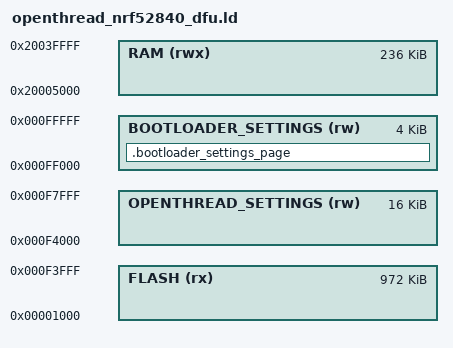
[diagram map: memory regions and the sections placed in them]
/* Linker script to configure memory regions. */

SEARCH_DIR(.)
GROUP(-lgcc -lc -lnosys)

MEMORY
{
  FLASH (rx) : ORIGIN = 0x1000, LENGTH = 0xF3000
  RAM (rwx) :  ORIGIN = 0x20005000, LENGTH = 0x3B000

  /** Location of bootloader setting in flash. */
  BOOTLOADER_SETTINGS (rw) : ORIGIN = 0x000FF000, LENGTH = 0x1000

  /** Location of OpenThread settings in flash. */
  OPENTHREAD_SETTINGS (rw) : ORIGIN = 0x000F4000, LENGTH = 0x4000
}

SECTIONS
{
  /* Place the bootloader settings page in flash. */
  .bootloader_settings_page(NOLOAD) :
  {

  } > BOOTLOADER_SETTINGS
}

SECTIONS
{
  . = ALIGN(4);
  .svc_data :
  {
    PROVIDE(__start_svc_data = .);
    KEEP(*(.svc_data))
    PROVIDE(__stop_svc_data = .);
  } > RAM
  .fs_data :
  {
    PROVIDE(__start_fs_data = .);
    KEEP(*(.fs_data))
    PROVIDE(__stop_fs_data = .);
  } > RAM
  .log_dynamic_data :
  {
    PROVIDE(__start_log_dynamic_data = .);
    KEEP(*(SORT(.log_dynamic_data*)))
    PROVIDE(__stop_log_dynamic_data = .);
  } > RAM
  .cli_sorted_cmd_ptrs :
  {
    PROVIDE(__start_cli_sorted_cmd_ptrs = .);
    KEEP(*(.cli_sorted_cmd_ptrs))
    PROVIDE(__stop_cli_sorted_cmd_ptrs = .);
  } > RAM
} INSERT AFTER .data;

SECTIONS
{
  .pwr_mgmt_data :
  {
    PROVIDE(__start_pwr_mgmt_data = .);
    KEEP(*(SORT(.pwr_mgmt_data*)))
    PROVIDE(__stop_pwr_mgmt_data = .);
  } > FLASH
  .log_const_data :
  {
    PROVIDE(__start_log_const_data = .);
    KEEP(*(SORT(.log_const_data*)))
    PROVIDE(__stop_log_const_data = .);
  } > FLASH
  .crypto_data :
  {
    PROVIDE(__start_crypto_data = .);
    KEEP(*(SORT(.crypto_data*)))
    PROVIDE(__stop_crypto_data = .);
  } > FLASH
  .nrf_balloc :
  {
    PROVIDE(__start_nrf_balloc = .);
    KEEP(*(.nrf_balloc))
    PROVIDE(__stop_nrf_balloc = .);
  } > FLASH
  .nrf_queue :
  {
    PROVIDE(__start_nrf_queue = .);
    KEEP(*(.nrf_queue))
    PROVIDE(__stop_nrf_queue = .);
  } > FLASH
  .cli_command :
  {
    PROVIDE(__start_cli_command = .);
    KEEP(*(.cli_command))
    PROVIDE(__stop_cli_command = .);
  } > FLASH
  .sdh_stack_observers :
  {
    PROVIDE(__start_sdh_stack_observers = .);
    KEEP(*(SORT(.sdh_stack_observers*)))
    PROVIDE(__stop_sdh_stack_observers = .);
  } > FLASH
  .sdh_req_observers :
  {
    PROVIDE(__start_sdh_req_observers = .);
    KEEP(*(SORT(.sdh_req_observers*)))
    PROVIDE(__stop_sdh_req_observers = .);
  } > FLASH
  .sdh_state_observers :
  {
    PROVIDE(__start_sdh_state_observers = .);
    KEEP(*(SORT(.sdh_state_observers*)))
    PROVIDE(__stop_sdh_state_observers = .);
  } > FLASH
  .sdh_ant_observers :
  {
    PROVIDE(__start_sdh_ant_observers = .);
    KEEP(*(SORT(.sdh_ant_observers*)))
    PROVIDE(__stop_sdh_ant_observers = .);
  } > FLASH
  .sdh_ble_observers :
  {
    PROVIDE(__start_sdh_ble_observers = .);
    KEEP(*(SORT(.sdh_ble_observers*)))
    PROVIDE(__stop_sdh_ble_observers = .);
  } > FLASH
  .sdh_soc_observers :
  {
    PROVIDE(__start_sdh_soc_observers = .);
    KEEP(*(SORT(.sdh_soc_observers*)))
    PROVIDE(__stop_sdh_soc_observers = .);
  } > FLASH
  .crypto_data :
  {
    PROVIDE(__start_crypto_data = .);
    KEEP(*(SORT(.crypto_data*)))
    PROVIDE(__stop_crypto_data = .);
  } > FLASH
} INSERT AFTER .text

SECTIONS
{
    __stop_ot_flash_data = (ORIGIN(OPENTHREAD_SETTINGS) + LENGTH(OPENTHREAD_SETTINGS));
    __start_ot_flash_data = ORIGIN(OPENTHREAD_SETTINGS);
}

INCLUDE "nrf_common.ld"
